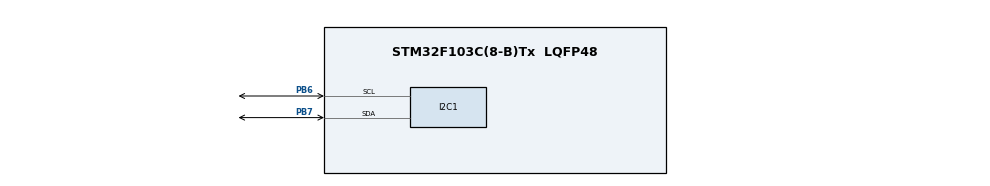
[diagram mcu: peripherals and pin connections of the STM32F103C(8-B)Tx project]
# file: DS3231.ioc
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Mcu.Family=STM32F1
Mcu.Name=STM32F103C(8-B)Tx
Mcu.Package=LQFP48
NVIC.PriorityGroup=NVIC_PRIORITYGROUP_4
PA13.Mode=Serial_Wire
PA13.Signal=SYS_JTMS-SWDIO
PA14.Mode=Serial_Wire
PA14.Signal=SYS_JTCK-SWCLK
PB6.Mode=I2C
PB6.Signal=I2C1_SCL
PB7.Mode=I2C
PB7.Signal=I2C1_SDA
PD0-OSC_IN.Mode=HSE-External-Oscillator
PD0-OSC_IN.Signal=RCC_OSC_IN
PD1-OSC_OUT.Mode=HSE-External-Oscillator
PD1-OSC_OUT.Signal=RCC_OSC_OUT
ProjectManager.HeapSize=0x200
ProjectManager.StackSize=0x400
ProjectManager.TargetToolchain=STM32CubeIDE
RCC.APB1Freq_Value=8000000
RCC.APB2Freq_Value=8000000
TIM2.Prescaler=72-1
VP_TIM2_VS_ClockSourceINT.Mode=Internal
board=custom

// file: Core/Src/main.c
/* USER CODE BEGIN Header */
/**
  ******************************************************************************
  * @file           : main.c
  * @brief          : Main program body
  ******************************************************************************
  * @attention
  *
  * Copyright (c) 2023 STMicroelectronics.
  * All rights reserved.
  *
  * This software is licensed under terms that can be found in the LICENSE file
  * in the root directory of this software component.
  * If no LICENSE file comes with this software, it is provided AS-IS.
  *
  ******************************************************************************
  */
/* USER CODE END Header */
#include "main.h"
#include "lcd_i2c.h"
#include "DS3231.h"

/* USER CODE BEGIN PTD */
	uint8_t device;
	DS3231_Time DS3231;
/* USER CODE END PTD */

I2C_HandleTypeDef hi2c1;

TIM_HandleTypeDef htim2;

/* USER CODE BEGIN PV */
LCD_I2C_HandleTypeDef p_lcd;
/* USER CODE END PV */

void SystemClock_Config(void);
static void MX_GPIO_Init(void);
static void MX_I2C1_Init(void);
static void MX_TIM2_Init(void);

/* USER CODE BEGIN 0 */
	char time[15];
/* USER CODE END 0 */

int main(void)
{

  /* MCU Configuration--------------------------------------------------------*/

  /* Reset of all peripherals, Initializes the Flash interface and the Systick. */
  HAL_Init();

  /* Configure the system clock */
  SystemClock_Config();

  /* Initialize all configured peripherals */
  MX_GPIO_Init();
  MX_I2C1_Init();
  MX_TIM2_Init();
  /* USER CODE BEGIN 2 */
  lcd_i2c_init(&p_lcd, &hi2c1, 20, 4, 0x27<<1);

  for (int i = 0; i < 255; i++)
  {
	   if (HAL_I2C_IsDeviceReady(&hi2c1, i, 1, 100) == HAL_OK)
	   {
		   device = i;
	   }
  }

  DS3231_Init(&DS3231, &hi2c1);
  //DS3231_SetTime(&DS3231, 0, 27, 11);
  //DS3231_SetDate(&DS3231, 5, 16, 3, 23);

  /* USER CODE END 2 */

  /* Infinite loop */
  while (1)
  {

    /* USER CODE BEGIN 3 */
	  DS3231_GetTime(&DS3231);
	  DS3231_GetDate(&DS3231);
	  HAL_Delay(200);

	  lcd_set_cursor(&p_lcd, 0, 0);
	  lcd_send_string(&p_lcd, "HELLO PhamTuan!");
	  sprintf(time, "%02d:%02d:%02d", DS3231.Hour, DS3231.Min, DS3231.Sec);
	  lcd_set_cursor(&p_lcd, 0, 1);
	  lcd_send_string(&p_lcd, time);
	  sprintf(time, "Thu%2d  %02d-%02d-20%02d",DS3231.Day, DS3231.Date, DS3231.Month, DS3231.Year);
	  lcd_set_cursor(&p_lcd, 0, 2);
	  lcd_send_string(&p_lcd, time);
	  lcd_set_cursor(&p_lcd, 0, 3);
	  lcd_send_string(&p_lcd, "HAVE A NICE DAY!");
	  HAL_Delay(200);
  }
  /* USER CODE END 3 */
}

void SystemClock_Config(void)
{
  RCC_OscInitTypeDef RCC_OscInitStruct = {0};
  RCC_ClkInitTypeDef RCC_ClkInitStruct = {0};

  /** Initializes the RCC Oscillators according to the specified parameters
  * in the RCC_OscInitTypeDef structure.
  */
  RCC_OscInitStruct.OscillatorType = RCC_OSCILLATORTYPE_HSI;
  RCC_OscInitStruct.HSIState = RCC_HSI_ON;
  RCC_OscInitStruct.HSICalibrationValue = RCC_HSICALIBRATION_DEFAULT;
  RCC_OscInitStruct.PLL.PLLState = RCC_PLL_NONE;
  if (HAL_RCC_OscConfig(&RCC_OscInitStruct) != HAL_OK)
  {
    Error_Handler();
  }

  /** Initializes the CPU, AHB and APB buses clocks
  */
  RCC_ClkInitStruct.ClockType = RCC_CLOCKTYPE_HCLK|RCC_CLOCKTYPE_SYSCLK
                              |RCC_CLOCKTYPE_PCLK1|RCC_CLOCKTYPE_PCLK2;
  RCC_ClkInitStruct.SYSCLKSource = RCC_SYSCLKSOURCE_HSI;
  RCC_ClkInitStruct.AHBCLKDivider = RCC_SYSCLK_DIV1;
  RCC_ClkInitStruct.APB1CLKDivider = RCC_HCLK_DIV1;
  RCC_ClkInitStruct.APB2CLKDivider = RCC_HCLK_DIV1;

  if (HAL_RCC_ClockConfig(&RCC_ClkInitStruct, FLASH_LATENCY_0) != HAL_OK)
  {
    Error_Handler();
  }
}

static void MX_I2C1_Init(void)
{

  hi2c1.Instance = I2C1;
  hi2c1.Init.ClockSpeed = 100000;
  hi2c1.Init.DutyCycle = I2C_DUTYCYCLE_2;
  hi2c1.Init.OwnAddress1 = 0;
  hi2c1.Init.AddressingMode = I2C_ADDRESSINGMODE_7BIT;
  hi2c1.Init.DualAddressMode = I2C_DUALADDRESS_DISABLE;
  hi2c1.Init.OwnAddress2 = 0;
  hi2c1.Init.GeneralCallMode = I2C_GENERALCALL_DISABLE;
  hi2c1.Init.NoStretchMode = I2C_NOSTRETCH_DISABLE;
  if (HAL_I2C_Init(&hi2c1) != HAL_OK)
  {
    Error_Handler();
  }

}

static void MX_TIM2_Init(void)
{

  TIM_ClockConfigTypeDef sClockSourceConfig = {0};
  TIM_MasterConfigTypeDef sMasterConfig = {0};

  htim2.Instance = TIM2;
  htim2.Init.Prescaler = 72-1;
  htim2.Init.CounterMode = TIM_COUNTERMODE_UP;
  htim2.Init.Period = 65535;
  htim2.Init.ClockDivision = TIM_CLOCKDIVISION_DIV1;
  htim2.Init.AutoReloadPreload = TIM_AUTORELOAD_PRELOAD_DISABLE;
  if (HAL_TIM_Base_Init(&htim2) != HAL_OK)
  {
    Error_Handler();
  }
  sClockSourceConfig.ClockSource = TIM_CLOCKSOURCE_INTERNAL;
  if (HAL_TIM_ConfigClockSource(&htim2, &sClockSourceConfig) != HAL_OK)
  {
    Error_Handler();
  }
  sMasterConfig.MasterOutputTrigger = TIM_TRGO_RESET;
  sMasterConfig.MasterSlaveMode = TIM_MASTERSLAVEMODE_DISABLE;
  if (HAL_TIMEx_MasterConfigSynchronization(&htim2, &sMasterConfig) != HAL_OK)
  {
    Error_Handler();
  }

}

static void MX_GPIO_Init(void)
{

  /* GPIO Ports Clock Enable */
  __HAL_RCC_GPIOD_CLK_ENABLE();
  __HAL_RCC_GPIOA_CLK_ENABLE();
  __HAL_RCC_GPIOB_CLK_ENABLE();

}

void Error_Handler(void)
{
  __disable_irq();
  while (1)
  {
  }
}
